# AM335x register map
Vendor: Texas Instruments; Series: Sitara AM335x; File version: 1.1
CPU: Cortex-A8 r0p0, little endian
Registers are 32-bit, read-write, reset 0x0 unless marked. A register's access mark holds for its fields unless they carry their own. Offsets are from the block's base; [hi:lo] are bit positions; {n}, {i} and the like mark numbered series; 'fields as' and 'values as' point back to an identical list.

## CM_PER — Clock Module - Peripheral
Base 0x44E00000
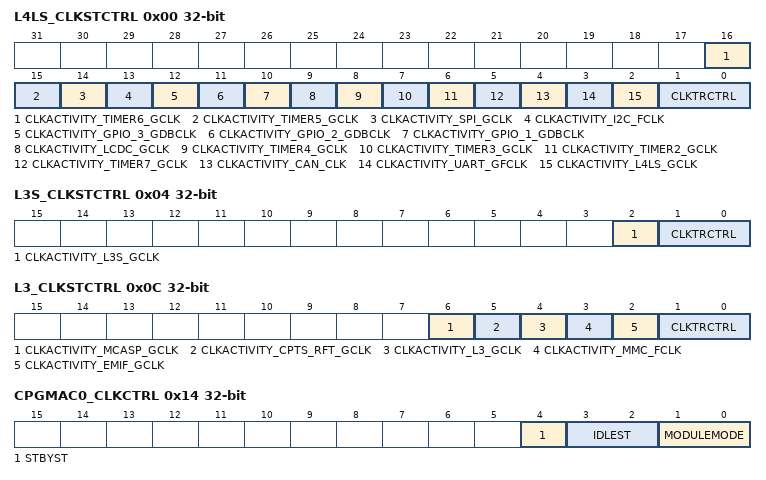
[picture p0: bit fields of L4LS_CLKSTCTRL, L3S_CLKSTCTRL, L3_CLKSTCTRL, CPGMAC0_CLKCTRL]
0x00 L4LS_CLKSTCTRL
  [16] CLKACTIVITY_TIMER6_GCLK — bit: 28 (R)state of the clock in domain [see e_PRCM_CLK_DOMAIN_ST]
  [15] CLKACTIVITY_TIMER5_GCLK — bit: 27 (R)state of the clock in domain [see e_PRCM_CLK_DOMAIN_ST]
  [14] CLKACTIVITY_SPI_GCLK — bit: 25 (R)state of the clock in domain [see e_PRCM_CLK_DOMAIN_ST]
  [13] CLKACTIVITY_I2C_FCLK — bit: 24 (R)state of the clock in domain [see e_PRCM_CLK_DOMAIN_ST]
  [12] CLKACTIVITY_GPIO_3_GDBCLK — bit: 21 (R)state of the clock in domain [see e_PRCM_CLK_DOMAIN_ST]
  [11] CLKACTIVITY_GPIO_2_GDBCLK — bit: 20 (R)state of the clock in domain [see e_PRCM_CLK_DOMAIN_ST]
  [10] CLKACTIVITY_GPIO_1_GDBCLK — bit: 19 (R)state of the clock in domain [see e_PRCM_CLK_DOMAIN_ST]
  [9] CLKACTIVITY_LCDC_GCLK — bit: 17 (R)state of the clock in domain [see e_PRCM_CLK_DOMAIN_ST]
  [8] CLKACTIVITY_TIMER4_GCLK — bit: 16 (R)state of the clock in domain [see e_PRCM_CLK_DOMAIN_ST]
  [7] CLKACTIVITY_TIMER3_GCLK — bit: 15 (R)state of the clock in domain [see e_PRCM_CLK_DOMAIN_ST]
  [6] CLKACTIVITY_TIMER2_GCLK — bit: 14 (R)state of the clock in domain [see e_PRCM_CLK_DOMAIN_ST]
  [5] CLKACTIVITY_TIMER7_GCLK — bit: 13 (R)state of the clock in domain [see e_PRCM_CLK_DOMAIN_ST]
  [4] CLKACTIVITY_CAN_CLK — bit: 11 (R)state of the clock in domain [see e_PRCM_CLK_DOMAIN_ST]
  [3] CLKACTIVITY_UART_GFCLK — bit: 10 (R)state of the clock in domain [see e_PRCM_CLK_DOMAIN_ST]
  [2] CLKACTIVITY_L4LS_GCLK — bit: 8 (R)state of the clock in domain [see e_PRCM_CLK_DOMAIN_ST]
  [1:0] CLKTRCTRL — bit: 0,1 (RW)Clock state transition [see e_PRCM_CLKTRCTRL]
0x04 L3S_CLKSTCTRL
  [2] CLKACTIVITY_L3S_GCLK — bit: 3 (R)state of the clock in domain [see e_PRCM_CLK_DOMAIN_ST]
  [1:0] CLKTRCTRL — bit: 0,1 (RW)Clock state transition [see e_PRCM_CLKTRCTRL]
0x0C L3_CLKSTCTRL
  [6] CLKACTIVITY_MCASP_GCLK — bit: 7 (R)state of the clock in domain [see e_PRCM_CLK_DOMAIN_ST]
  [5] CLKACTIVITY_CPTS_RFT_GCLK — bit: 6 (R)state of the clock in domain [see e_PRCM_CLK_DOMAIN_ST]
  [4] CLKACTIVITY_L3_GCLK — bit: 4 (R)state of the clock in domain [see e_PRCM_CLK_DOMAIN_ST]
  [3] CLKACTIVITY_MMC_FCLK — bit: 3 (R)state of the clock in domain [see e_PRCM_CLK_DOMAIN_ST]
  [2] CLKACTIVITY_EMIF_GCLK — bit: 2 (R)state of the clock in domain [see e_PRCM_CLK_DOMAIN_ST]
  [1:0] CLKTRCTRL — bit: 0,1 (RW)Clock state transition[see e_PRCM_CLKTRCTRL]
0x14 CPGMAC0_CLKCTRL — CM_STBY_CLKCTRL Register
  [4] STBYST — bit: 18 (R)Module standby status.[see e_PRCM_STBYST]
  [3:2] IDLEST — bit: 16,17 (R)Module idle status.[see e_PRCM_IDLEST]
  [1:0] MODULEMODE — bit: 0,1 (RW)Control the way mandatory clocks are managed.[see e_PRCM_MODULEMODE]
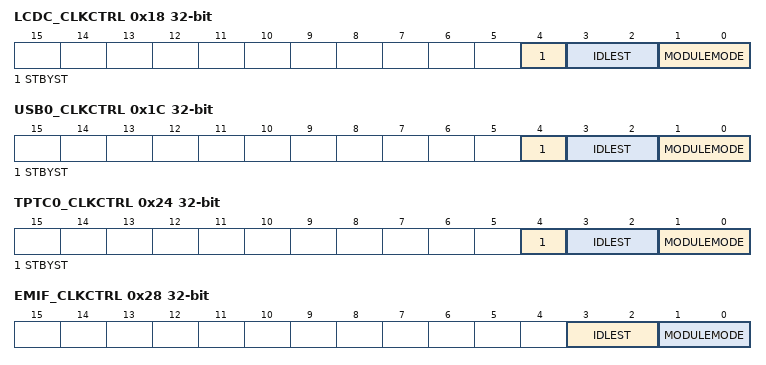
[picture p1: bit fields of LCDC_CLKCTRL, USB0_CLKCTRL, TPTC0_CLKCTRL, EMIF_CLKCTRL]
0x18 LCDC_CLKCTRL — CM_STBY_CLKCTRL Register
  fields as CPGMAC0_CLKCTRL
0x1C USB0_CLKCTRL — CM_STBY_CLKCTRL Register
  fields as CPGMAC0_CLKCTRL
0x24 TPTC0_CLKCTRL — CM_STBY_CLKCTRL Register
  fields as CPGMAC0_CLKCTRL
0x28 EMIF_CLKCTRL — CM_CLKCTRL Register
  [3:2] IDLEST — bit: 16,17 (R)Module idle status.[see e_PRCM_IDLEST]
  [1:0] MODULEMODE — bit: 0,1 (RW)Control the way mandatory clocks are managed.[see e_PRCM_MODULEMODE]
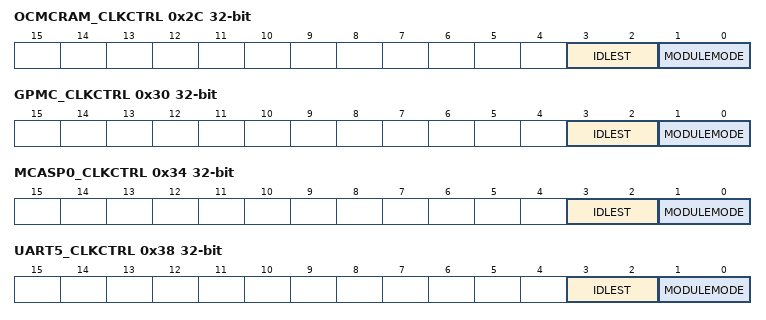
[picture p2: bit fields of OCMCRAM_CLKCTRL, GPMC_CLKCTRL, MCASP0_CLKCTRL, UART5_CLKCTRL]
0x2C OCMCRAM_CLKCTRL — CM_CLKCTRL Register
  fields as EMIF_CLKCTRL
0x30 GPMC_CLKCTRL — CM_CLKCTRL Register
  fields as EMIF_CLKCTRL
0x34 MCASP0_CLKCTRL — CM_CLKCTRL Register
  fields as EMIF_CLKCTRL
0x38 UART5_CLKCTRL — CM_CLKCTRL Register
  fields as EMIF_CLKCTRL
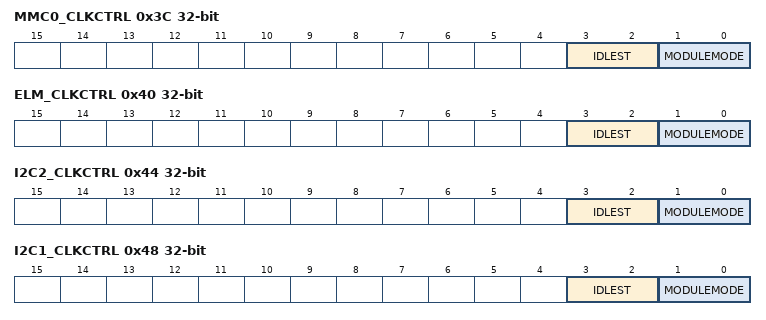
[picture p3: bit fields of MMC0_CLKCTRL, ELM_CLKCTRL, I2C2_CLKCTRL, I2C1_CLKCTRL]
0x3C MMC0_CLKCTRL — CM_CLKCTRL Register
  fields as EMIF_CLKCTRL
0x40 ELM_CLKCTRL — CM_CLKCTRL Register
  fields as EMIF_CLKCTRL
0x44 I2C2_CLKCTRL — CM_CLKCTRL Register
  fields as EMIF_CLKCTRL
0x48 I2C1_CLKCTRL — CM_CLKCTRL Register
  fields as EMIF_CLKCTRL
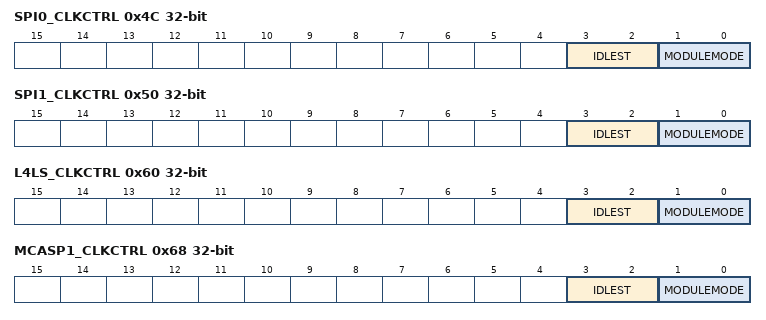
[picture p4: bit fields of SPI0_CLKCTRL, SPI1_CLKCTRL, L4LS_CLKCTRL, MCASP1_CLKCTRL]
0x4C SPI0_CLKCTRL — CM_CLKCTRL Register
  fields as EMIF_CLKCTRL
0x50 SPI1_CLKCTRL — CM_CLKCTRL Register
  fields as EMIF_CLKCTRL
0x60 L4LS_CLKCTRL — CM_CLKCTRL Register
  fields as EMIF_CLKCTRL
0x68 MCASP1_CLKCTRL — CM_CLKCTRL Register
  fields as EMIF_CLKCTRL
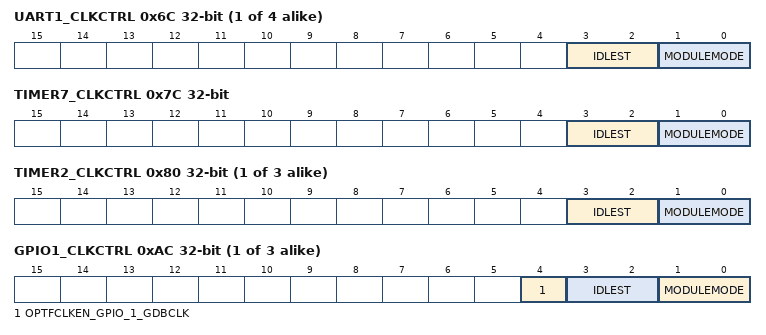
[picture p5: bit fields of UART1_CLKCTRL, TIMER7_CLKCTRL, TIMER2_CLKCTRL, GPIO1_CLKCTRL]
{0x68+4i} UART{i}_CLKCTRL (i=1..4) — CM_CLKCTRL Register
  fields as EMIF_CLKCTRL
0x7C TIMER7_CLKCTRL — CM_CLKCTRL Register
  fields as EMIF_CLKCTRL
{0x78+4i} TIMER{i}_CLKCTRL (i=2..4) — CM_CLKCTRL Register
  fields as EMIF_CLKCTRL
{0xA8+4i} GPIO{i}_CLKCTRL (i=1..3)
  [4] OPTFCLKEN_GPIO_{i}_GDBCLK — bit: 18 (RW)Optional functional clock control [0x0 = FCLK_DIS; 0x1 = FCLK_EN]
  [3:2] IDLEST — bit: 16,17 (R)Module idle status.[see e_PRCM_IDLEST]
  [1:0] MODULEMODE — bit: 0,1 (RW)Control the way mandatory clocks are managed.[see e_PRCM_MODULEMODE]
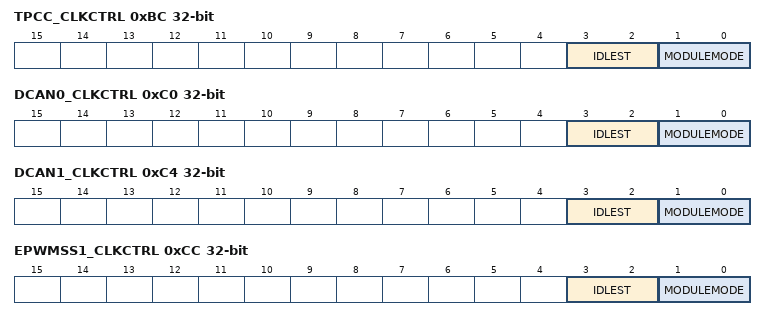
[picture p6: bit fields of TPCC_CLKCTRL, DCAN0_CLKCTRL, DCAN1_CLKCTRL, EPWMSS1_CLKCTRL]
0xBC TPCC_CLKCTRL — CM_CLKCTRL Register
  fields as EMIF_CLKCTRL
0xC0 DCAN0_CLKCTRL — CM_CLKCTRL Register
  fields as EMIF_CLKCTRL
0xC4 DCAN1_CLKCTRL — CM_CLKCTRL Register
  fields as EMIF_CLKCTRL
0xCC EPWMSS1_CLKCTRL — CM_CLKCTRL Register
  fields as EMIF_CLKCTRL
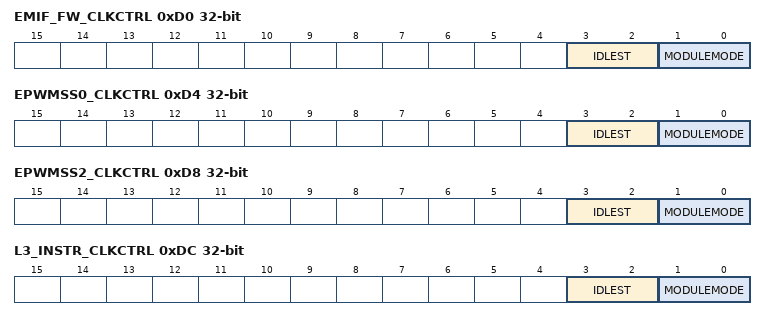
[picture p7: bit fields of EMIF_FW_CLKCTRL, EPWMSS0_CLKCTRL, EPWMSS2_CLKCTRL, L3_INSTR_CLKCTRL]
0xD0 EMIF_FW_CLKCTRL — CM_CLKCTRL Register
  fields as EMIF_CLKCTRL
0xD4 EPWMSS0_CLKCTRL — CM_CLKCTRL Register
  fields as EMIF_CLKCTRL
0xD8 EPWMSS2_CLKCTRL — CM_CLKCTRL Register
  fields as EMIF_CLKCTRL
0xDC L3_INSTR_CLKCTRL — CM_CLKCTRL Register
  fields as EMIF_CLKCTRL
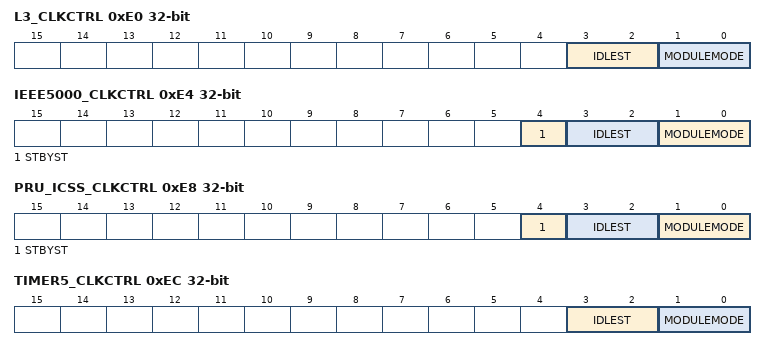
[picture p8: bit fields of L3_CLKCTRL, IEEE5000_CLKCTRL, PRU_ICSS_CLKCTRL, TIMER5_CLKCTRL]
0xE0 L3_CLKCTRL — CM_CLKCTRL Register
  fields as EMIF_CLKCTRL
0xE4 IEEE5000_CLKCTRL — CM_STBY_CLKCTRL Register
  fields as CPGMAC0_CLKCTRL
0xE8 PRU_ICSS_CLKCTRL — CM_STBY_CLKCTRL Register
  fields as CPGMAC0_CLKCTRL
0xEC TIMER5_CLKCTRL — CM_CLKCTRL Register
  fields as EMIF_CLKCTRL
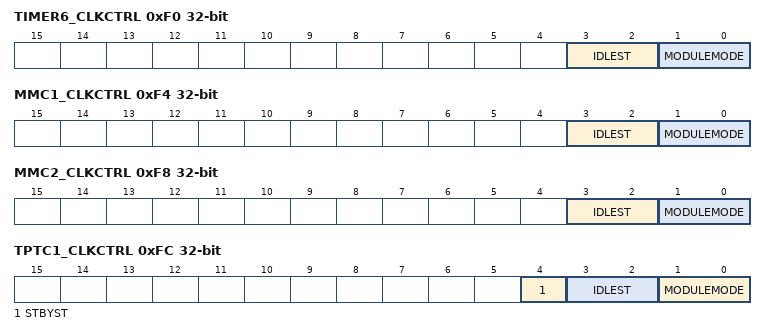
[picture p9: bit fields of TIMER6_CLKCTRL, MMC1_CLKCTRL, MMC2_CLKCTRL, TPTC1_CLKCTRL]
0xF0 TIMER6_CLKCTRL — CM_CLKCTRL Register
  fields as EMIF_CLKCTRL
0xF4 MMC1_CLKCTRL — CM_CLKCTRL Register
  fields as EMIF_CLKCTRL
0xF8 MMC2_CLKCTRL — CM_CLKCTRL Register
  fields as EMIF_CLKCTRL
0xFC TPTC1_CLKCTRL — CM_STBY_CLKCTRL Register
  fields as CPGMAC0_CLKCTRL
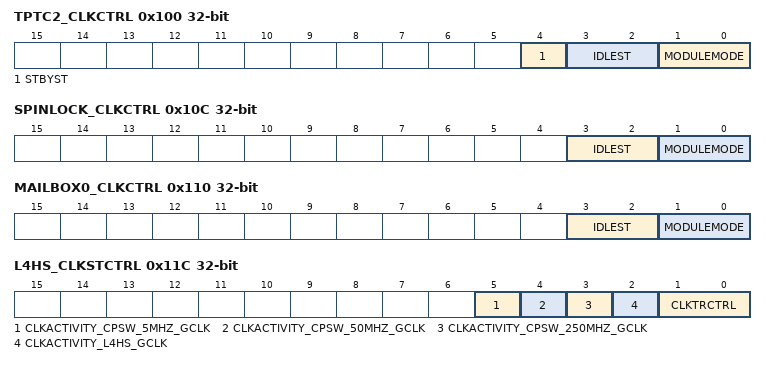
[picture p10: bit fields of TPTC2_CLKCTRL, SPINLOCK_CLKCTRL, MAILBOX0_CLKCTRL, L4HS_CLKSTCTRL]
0x100 TPTC2_CLKCTRL — CM_STBY_CLKCTRL Register
  fields as CPGMAC0_CLKCTRL
0x10C SPINLOCK_CLKCTRL — CM_CLKCTRL Register
  fields as EMIF_CLKCTRL
0x110 MAILBOX0_CLKCTRL — CM_CLKCTRL Register
  fields as EMIF_CLKCTRL
0x11C L4HS_CLKSTCTRL
  [5] CLKACTIVITY_CPSW_5MHZ_GCLK — bit: 6 (R)state of the clock in domain [see e_PRCM_CLK_DOMAIN_ST]
  [4] CLKACTIVITY_CPSW_50MHZ_GCLK — bit: 5 (R)state of the clock in domain [see e_PRCM_CLK_DOMAIN_ST]
  [3] CLKACTIVITY_CPSW_250MHZ_GCLK — bit: 4 (R)state of the clock in domain [see e_PRCM_CLK_DOMAIN_ST]
  [2] CLKACTIVITY_L4HS_GCLK — bit: 3 (R)state of the clock in domain [see e_PRCM_CLK_DOMAIN_ST]
  [1:0] CLKTRCTRL — bit: 0,1 (RW)Clock state transition [see e_PRCM_CLKTRCTRL]
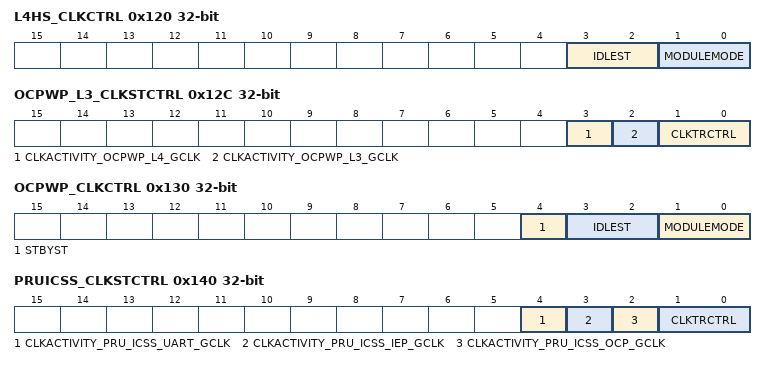
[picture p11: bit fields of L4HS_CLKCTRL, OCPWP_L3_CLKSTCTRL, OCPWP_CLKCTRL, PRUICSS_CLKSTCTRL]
0x120 L4HS_CLKCTRL — CM_CLKCTRL Register
  fields as EMIF_CLKCTRL
0x12C OCPWP_L3_CLKSTCTRL
  [3] CLKACTIVITY_OCPWP_L4_GCLK — bit: 5 (R)state of the clock in domain [see e_PRCM_CLK_DOMAIN_ST]
  [2] CLKACTIVITY_OCPWP_L3_GCLK — bit: 4 (R)state of the clock in domain [see e_PRCM_CLK_DOMAIN_ST]
  [1:0] CLKTRCTRL — bit: 0,1 (RW)Clock state transition [see e_PRCM_CLKTRCTRL]
0x130 OCPWP_CLKCTRL — CM_STBY_CLKCTRL Register
  fields as CPGMAC0_CLKCTRL
0x140 PRUICSS_CLKSTCTRL
  [4] CLKACTIVITY_PRU_ICSS_UART_GCLK — bit: 6 (R)state of the clock in domain [see e_PRCM_CLK_DOMAIN_ST]
  [3] CLKACTIVITY_PRU_ICSS_IEP_GCLK — bit: 5 (R)state of the clock in domain [see e_PRCM_CLK_DOMAIN_ST]
  [2] CLKACTIVITY_PRU_ICSS_OCP_GCLK — bit: 4 (R)state of the clock in domain [see e_PRCM_CLK_DOMAIN_ST]
  [1:0] CLKTRCTRL — bit: 0,1 (RW)Clock state transition [see e_PRCM_CLKTRCTRL]
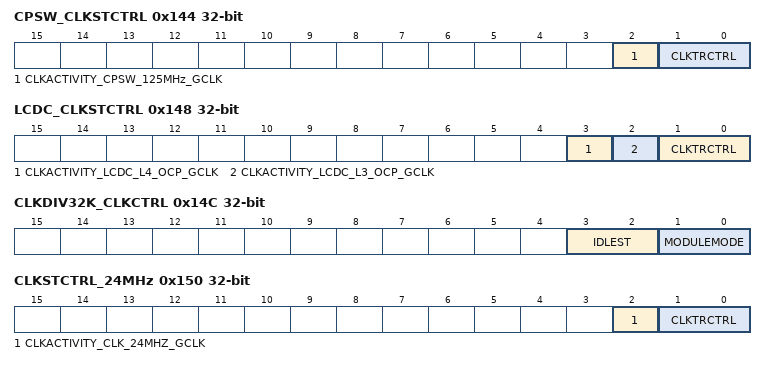
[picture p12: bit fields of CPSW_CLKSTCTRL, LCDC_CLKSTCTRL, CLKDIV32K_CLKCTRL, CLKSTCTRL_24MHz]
0x144 CPSW_CLKSTCTRL
  [2] CLKACTIVITY_CPSW_125MHz_GCLK — bit: 4 (R)state of the clock in domain [see e_PRCM_CLK_DOMAIN_ST]
  [1:0] CLKTRCTRL — bit: 0,1 (RW)Clock state transition [see e_PRCM_CLKTRCTRL]
0x148 LCDC_CLKSTCTRL
  [3] CLKACTIVITY_LCDC_L4_OCP_GCLK — bit: 5 (R)state of the clock in domain [see e_PRCM_CLK_DOMAIN_ST]
  [2] CLKACTIVITY_LCDC_L3_OCP_GCLK — bit: 4 (R)state of the clock in domain [see e_PRCM_CLK_DOMAIN_ST]
  [1:0] CLKTRCTRL — bit: 0,1 (RW)Clock state transition [see e_PRCM_CLKTRCTRL]
0x14C CLKDIV32K_CLKCTRL — CM_CLKCTRL Register
  fields as EMIF_CLKCTRL
0x150 CLKSTCTRL_24MHz
  [2] CLKACTIVITY_CLK_24MHZ_GCLK — bit: 4 (R)state of the clock in domain [see e_PRCM_CLK_DOMAIN_ST]
  [1:0] CLKTRCTRL — bit: 0,1 (RW)Clock state transition [see e_PRCM_CLKTRCTRL]
